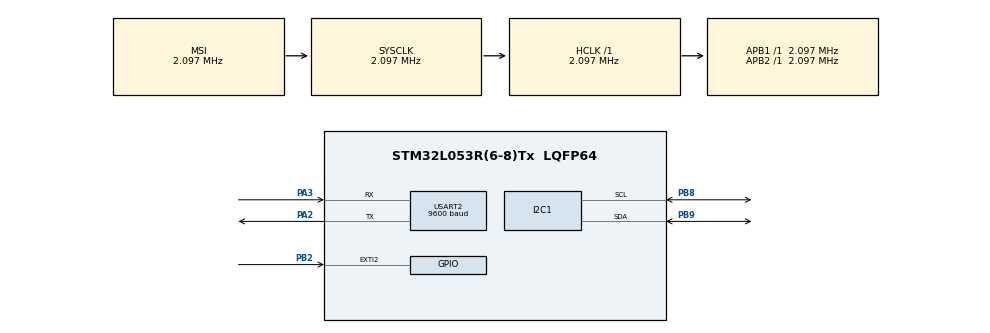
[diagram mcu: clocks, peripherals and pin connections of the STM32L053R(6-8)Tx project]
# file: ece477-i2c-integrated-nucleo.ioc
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Mcu.Family=STM32L0
RCC.MSI_VALUE=2097000
NVIC.TIM6_DAC_IRQn=true\:0\:0\:false\:true\:true\:1\:true\:true
TIM6.Prescaler=2097-1
VP_TIM6_VS_ClockSourceINT.Mode=Enable_Timer
USART2.BaudRate=9600
ProjectManager.StackSize=0x400
PA3.Mode=Asynchronous
PB2.GPIO_ModeDefaultEXTI=GPIO_MODE_IT_FALLING
RCC.HSI16_VALUE=16000000
ProjectManager.TargetToolchain=STM32CubeIDE
PB9.Mode=I2C
RCC.APB2TimFreq_Value=2097000
RCC.LSE_VALUE=32768
RCC.AHBFreq_Value=2097000
RCC.HSE_VALUE=8000000
PB2.Signal=GPXTI2
board=custom
USART2.VirtualMode-Asynchronous=VM_ASYNC
RCC.VCOOutputFreq_Value=48000000
NVIC.EXTI2_3_IRQn=true\:3\:0\:true\:false\:true\:true\:true
RCC.APB2Freq_Value=2097000
TIM6.Period=1000-1
Mcu.Name=STM32L053R(6-8)Tx
PA2.Signal=USART2_TX
RCC.SYSCLKFreq_VALUE=2097000
Mcu.Package=LQFP64
PB9.Signal=I2C1_SDA
ProjectManager.HeapSize=0x200
RCC.HSI_VALUE=16000000
PB8.Mode=I2C
RCC.APB1TimFreq_Value=2097000
PA2.Mode=Asynchronous
PB8.Signal=I2C1_SCL
RCC.APB1Freq_Value=2097000
RCC.HSI48_VALUE=48000000
PA3.Signal=USART2_RX

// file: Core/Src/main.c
/* USER CODE BEGIN Header */
/**
  ******************************************************************************
  * @file           : main.c
  * @brief          : Main program body
  ******************************************************************************
  * @attention
  *
  * <h2><center>&copy; Copyright (c) 2021 STMicroelectronics.
  * All rights reserved.</center></h2>
  *
  * This software component is licensed by ST under BSD 3-Clause license,
  * the "License"; You may not use this file except in compliance with the
  * License. You may obtain a copy of the License at:
  *                        opensource.org/licenses/BSD-3-Clause
  *
  ******************************************************************************
  */
/* USER CODE END Header */
#include "main.h"
#include "i2c.h"
#include "tim.h"
#include "usart.h"
#include "gpio.h"

/* USER CODE BEGIN Includes */
#include "hts221.h"
#include "bq27441.h"
#include "vcnl4010.h"
#include "serial_print.h"
/* USER CODE END Includes */

/* USER CODE BEGIN PV */
HTS_Cal * hts_cal_data;
int bq_init_ret;

//TODO - make this an enum? for battery state?
int state = 0;

/* USER CODE END PV */

void SystemClock_Config(void);
static void MX_NVIC_Init(void);

int main(void)
{

  /* MCU Configuration--------------------------------------------------------*/

  /* Reset of all peripherals, Initializes the Flash interface and the Systick. */
  HAL_Init();

  /* Configure the system clock */
  SystemClock_Config();

  /* Initialize all configured peripherals */
  MX_GPIO_Init();
  MX_I2C1_Init();
  MX_USART2_UART_Init();
  MX_TIM6_Init();

  /* Initialize interrupts */
  MX_NVIC_Init();
  /* USER CODE BEGIN 2 */

  serial_clear();
  serial_println("Hello world\n\n");
//  serial_printf("state = %d\n", state);

  hts_cal_data = hts221_init();
  bq_init_ret = bq_init();
  VCNL4010_setLEDcurrent(20);
  VCNL4010_enable_Interrupt();

  HAL_TIM_Base_Start_IT(&htim6);

  /* USER CODE END 2 */

  /* Infinite loop */
  while (1)
  {

  }
}

void SystemClock_Config(void)
{
  RCC_OscInitTypeDef RCC_OscInitStruct = {0};
  RCC_ClkInitTypeDef RCC_ClkInitStruct = {0};
  RCC_PeriphCLKInitTypeDef PeriphClkInit = {0};

  /** Configure the main internal regulator output voltage
  */
  __HAL_PWR_VOLTAGESCALING_CONFIG(PWR_REGULATOR_VOLTAGE_SCALE1);
  /** Initializes the RCC Oscillators according to the specified parameters
  * in the RCC_OscInitTypeDef structure.
  */
  RCC_OscInitStruct.OscillatorType = RCC_OSCILLATORTYPE_MSI;
  RCC_OscInitStruct.MSIState = RCC_MSI_ON;
  RCC_OscInitStruct.MSICalibrationValue = 0;
  RCC_OscInitStruct.MSIClockRange = RCC_MSIRANGE_5;
  RCC_OscInitStruct.PLL.PLLState = RCC_PLL_NONE;
  if (HAL_RCC_OscConfig(&RCC_OscInitStruct) != HAL_OK)
  {
    Error_Handler();
  }
  /** Initializes the CPU, AHB and APB buses clocks
  */
  RCC_ClkInitStruct.ClockType = RCC_CLOCKTYPE_HCLK|RCC_CLOCKTYPE_SYSCLK
                              |RCC_CLOCKTYPE_PCLK1|RCC_CLOCKTYPE_PCLK2;
  RCC_ClkInitStruct.SYSCLKSource = RCC_SYSCLKSOURCE_MSI;
  RCC_ClkInitStruct.AHBCLKDivider = RCC_SYSCLK_DIV1;
  RCC_ClkInitStruct.APB1CLKDivider = RCC_HCLK_DIV1;
  RCC_ClkInitStruct.APB2CLKDivider = RCC_HCLK_DIV1;

  if (HAL_RCC_ClockConfig(&RCC_ClkInitStruct, FLASH_LATENCY_0) != HAL_OK)
  {
    Error_Handler();
  }
  PeriphClkInit.PeriphClockSelection = RCC_PERIPHCLK_USART2|RCC_PERIPHCLK_I2C1;
  PeriphClkInit.Usart2ClockSelection = RCC_USART2CLKSOURCE_PCLK1;
  PeriphClkInit.I2c1ClockSelection = RCC_I2C1CLKSOURCE_PCLK1;
  if (HAL_RCCEx_PeriphCLKConfig(&PeriphClkInit) != HAL_OK)
  {
    Error_Handler();
  }
}

/**
  * @brief NVIC Configuration.
  * @retval None
  */
static void MX_NVIC_Init(void)
{
  /* TIM6_DAC_IRQn interrupt configuration */
  HAL_NVIC_SetPriority(TIM6_DAC_IRQn, 0, 0);
  HAL_NVIC_EnableIRQ(TIM6_DAC_IRQn);
}

void Error_Handler(void)
{
  __disable_irq();
  while (1)
  {
  }
}

/************************ (C) COPYRIGHT STMicroelectronics *****END OF FILE****/
